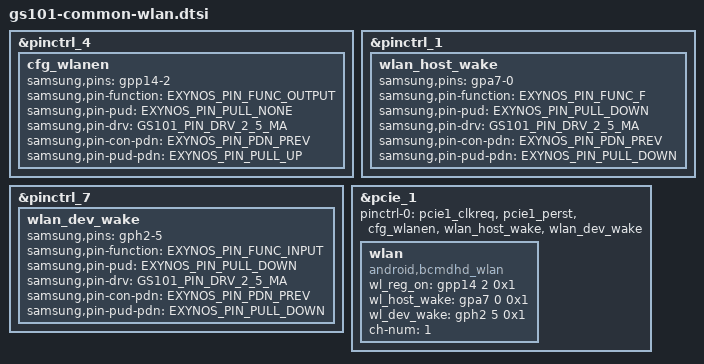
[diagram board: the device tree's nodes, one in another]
// SPDX-License-Identifier: GPL-2.0-only
/*
 * Google GS101 wlan device tree source
 *
 * Copyright 2020 Google,LLC
 */

#include <dt-bindings/gpio/gpio.h>
#include <dt-bindings/interrupt-controller/irq.h>
#include <dt-bindings/pinctrl/samsung.h>

&pinctrl_4 {
	cfg_wlanen: cfg_wlanen {
		samsung,pins = "gpp14-2";
		samsung,pin-function = <EXYNOS_PIN_FUNC_OUTPUT>;
		samsung,pin-pud = <EXYNOS_PIN_PULL_NONE>;
		samsung,pin-drv = <GS101_PIN_DRV_2_5_MA>;
		samsung,pin-con-pdn = <EXYNOS_PIN_PDN_PREV>;
		samsung,pin-pud-pdn = <EXYNOS_PIN_PULL_UP>;
	};
};

&pinctrl_1 {
	wlan_host_wake: wlan_host_wake {
		samsung,pins = "gpa7-0";
		samsung,pin-function = <EXYNOS_PIN_FUNC_F>;
		samsung,pin-pud = <EXYNOS_PIN_PULL_DOWN>;
		samsung,pin-drv = <GS101_PIN_DRV_2_5_MA>;
		samsung,pin-con-pdn = <EXYNOS_PIN_PDN_PREV>;
		samsung,pin-pud-pdn = <EXYNOS_PIN_PULL_DOWN>;
	};
};

&pinctrl_7 {
	wlan_dev_wake: wlan_dev_wake {
		samsung,pins = "gph2-5";
		samsung,pin-function = <EXYNOS_PIN_FUNC_INPUT>;
		samsung,pin-pud = <EXYNOS_PIN_PULL_DOWN>;
		samsung,pin-drv = <GS101_PIN_DRV_2_5_MA>;
		samsung,pin-con-pdn = <EXYNOS_PIN_PDN_PREV>;
		samsung,pin-pud-pdn = <EXYNOS_PIN_PULL_DOWN>;
	};
};

&pcie_1 {
	pinctrl-0 = <&pcie1_clkreq &pcie1_perst &cfg_wlanen &wlan_host_wake &wlan_dev_wake>;

	wlan {
		compatible = "android,bcmdhd_wlan";
		wl_reg_on = <&gpp14 2 0x1>; /* wlan reg_on pin */
		wl_host_wake = <&gpa7 0 0x1>; /* wlan oob pin */
		wl_dev_wake = <&gph2 5 0x1>; /* wlan dev pin */
		ch-num = <1>;
		status = "okay";
	};
};
